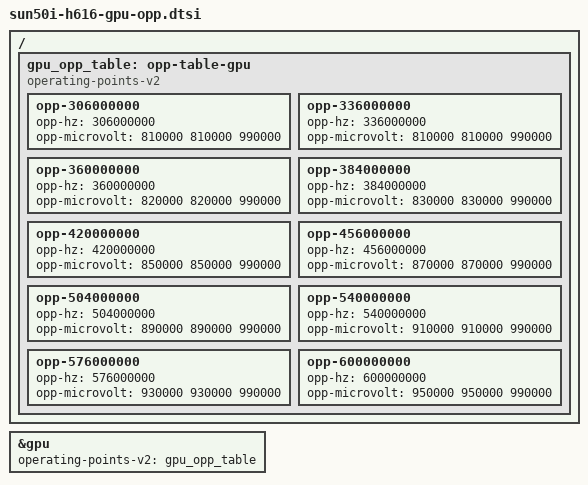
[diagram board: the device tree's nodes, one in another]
// SPDX-License-Identifier: (GPL-2.0+ OR MIT)
// Copyright (C) 2026 Arun Iyengar <aiyengar1990@gmail.com>

/ {
	gpu_opp_table: opp-table-gpu {
		compatible = "operating-points-v2";

		opp-306000000 {
			opp-hz = /bits/ 64 <306000000>;
			opp-microvolt = <810000 810000 990000>;
		};

		opp-336000000 {
			opp-hz = /bits/ 64 <336000000>;
			opp-microvolt = <810000 810000 990000>;
		};

		opp-360000000 {
			opp-hz = /bits/ 64 <360000000>;
			opp-microvolt = <820000 820000 990000>;
		};

		opp-384000000 {
			opp-hz = /bits/ 64 <384000000>;
			opp-microvolt = <830000 830000 990000>;
		};

		opp-420000000 {
			opp-hz = /bits/ 64 <420000000>;
			opp-microvolt = <850000 850000 990000>;
		};

		opp-456000000 {
			opp-hz = /bits/ 64 <456000000>;
			opp-microvolt = <870000 870000 990000>;
		};

		opp-504000000 {
			opp-hz = /bits/ 64 <504000000>;
			opp-microvolt = <890000 890000 990000>;
		};

		opp-540000000 {
			opp-hz = /bits/ 64 <540000000>;
			opp-microvolt = <910000 910000 990000>;
		};

		opp-576000000 {
			opp-hz = /bits/ 64 <576000000>;
			opp-microvolt = <930000 930000 990000>;
		};

		opp-600000000 {
			opp-hz = /bits/ 64 <600000000>;
			opp-microvolt = <950000 950000 990000>;
		};
	};
};

&gpu {
	operating-points-v2 = <&gpu_opp_table>;
};
